# MSPM0G350X register map
Vendor: Texas Instruments; File version: This preliminary header file does not have a version number - build date: 2023-02-21 16:25:48
CPU: CM0 r0p1, little endian, MPU, no FPU, 3 interrupt priority bits
Registers are 32-bit, read-write, reset 0x0 unless marked. A register's access mark holds for its fields unless they carry their own. Offsets are from the block's base; [hi:lo] are bit positions; {n}, {i} and the like mark numbered series.

## SPI1 — PERIPHERALREGION
Base 0x4046A000
Same registers: SPI0 0x40468000
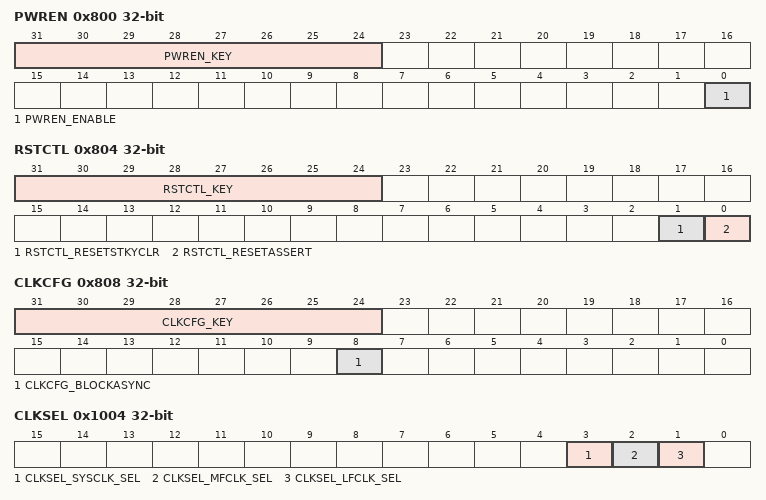
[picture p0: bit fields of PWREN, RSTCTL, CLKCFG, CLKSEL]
0x800 PWREN — Power enable
  [31:24] PWREN_KEY wo — KEY to allow Power State Change
    38=PWREN_KEY_UNLOCK_W (_TO_UNLOCK_W_)
  [0] PWREN_ENABLE — Enable the power
    0=PWREN_ENABLE_DISABLE (DISABLE); 1=PWREN_ENABLE_ENABLE (ENABLE)
0x804 RSTCTL wo — Reset Control
  [31:24] RSTCTL_KEY — Unlock key
    177=RSTCTL_KEY_UNLOCK_W (_TO_UNLOCK_W_)
  [1] RSTCTL_RESETSTKYCLR — Clear the RESETSTKY bit in the STAT register
    0=RSTCTL_RESETSTKYCLR_NOP (NOP); 1=RSTCTL_RESETSTKYCLR_CLR (CLR)
  [0] RSTCTL_RESETASSERT — Assert reset to the peripheral
    0=RSTCTL_RESETASSERT_NOP (NOP); 1=RSTCTL_RESETASSERT_ASSERT (ASSERT)
0x808 CLKCFG — Peripheral Clock Configuration Register
  [31:24] CLKCFG_KEY wo — KEY to Allow State Change -- 0xA9
    169=CLKCFG_KEY_UNLOCK (_UNLOCK_W_)
  [8] CLKCFG_BLOCKASYNC — Async Clock Request is blocked from starting SYSOSC or forcing bus clock to 32MHz
    0=CLKCFG_BLOCKASYNC_DISABLE (DISABLE); 1=CLKCFG_BLOCKASYNC_ENABLE (ENABLE)
0x814 GPRCM_STAT ro — Status Register
  [16] GPRCM_STAT_RESETSTKY — This bit indicates, if the peripheral was reset, since this bit was cleared by RESETSTKYCLR in the RSTCTL register
    0=GPRCM_STAT_RESETSTKY_NORES (NORES); 1=GPRCM_STAT_RESETSTKY_RESET (RESET)
0x1000 CLKDIV — Clock Divider
  [2:0] CLKDIV_RATIO — Selects divide ratio of module clock
    {v}=CLKDIV_RATIO_DIV_BY_{v+1} (DIV_BY_{v+1}) (v=0..7)
0x1004 CLKSEL — Clock Select for Ultra Low Power peripherals
  [3] CLKSEL_SYSCLK_SEL — Selects SYSCLK as clock source if enabled
    0=CLKSEL_SYSCLK_SEL_DISABLE (DISABLE); 1=CLKSEL_SYSCLK_SEL_ENABLE (ENABLE)
  [2] CLKSEL_MFCLK_SEL — Selects MFCLK as clock source if enabled
    0=CLKSEL_MFCLK_SEL_DISABLE (DISABLE); 1=CLKSEL_MFCLK_SEL_ENABLE (ENABLE)
  [1] CLKSEL_LFCLK_SEL — Selects LFCLK as clock source if enabled
    0=CLKSEL_LFCLK_SEL_DISABLE (DISABLE); 1=CLKSEL_LFCLK_SEL_ENABLE (ENABLE)
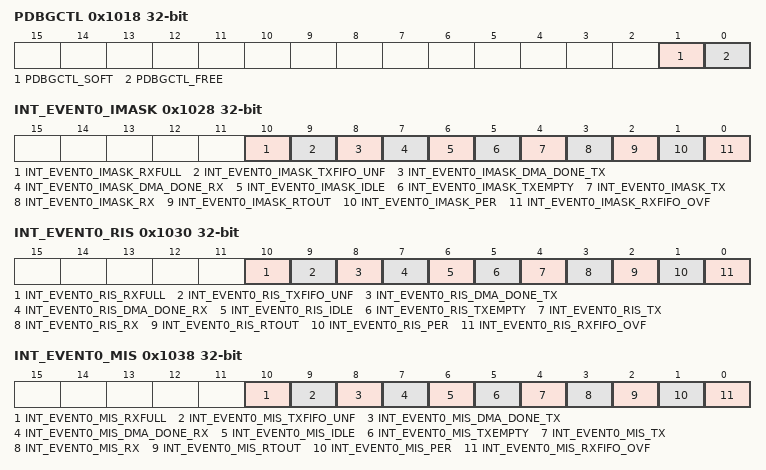
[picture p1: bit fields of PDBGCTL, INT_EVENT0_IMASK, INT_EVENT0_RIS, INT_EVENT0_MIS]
0x1018 PDBGCTL — Peripheral Debug Control
  [1] PDBGCTL_SOFT — Soft halt boundary control. This function is only available, if [FREE] is set to 'STOP'
    0=PDBGCTL_SOFT_IMMEDIATE (IMMEDIATE); 1=PDBGCTL_SOFT_DELAYED (DELAYED)
  [0] PDBGCTL_FREE — Free run control
    0=PDBGCTL_FREE_STOP (STOP); 1=PDBGCTL_FREE_RUN (RUN)
0x1020 INT_EVENT0_IIDX ro — Interrupt Index Register
  [7:0] INT_EVENT0_IIDX_STAT — Interrupt index status
    0=INT_EVENT0_IIDX_STAT_NO_INTR (NO_INTR); 1=INT_EVENT0_IIDX_STAT_RXFIFO_OFV_EVT (RXFIFO_OFV_EVT); 2=INT_EVENT0_IIDX_STAT_PER_EVT (PER_EVT); 3=INT_EVENT0_IIDX_STAT_RTOUT_EVT (RTOUT_EVT); 4=INT_EVENT0_IIDX_STAT_RX_EVT (RX_EVT); 5=INT_EVENT0_IIDX_STAT_TX_EVT (TX_EVT); 6=INT_EVENT0_IIDX_STAT_TX_EMPTY (TX_EMPTY); 7=INT_EVENT0_IIDX_STAT_IDLE_EVT (IDLE_EVT); 8=INT_EVENT0_IIDX_STAT_DMA_DONE_RX_EVT (DMA_DONE_RX_EVT); 9=INT_EVENT0_IIDX_STAT_DMA_DONE_TX_EVT (DMA_DONE_TX_EVT); 10=INT_EVENT0_IIDX_STAT_TXFIFO_UNF_EVT (TXFIFO_UNF_EVT); 11=INT_EVENT0_IIDX_STAT_RXFULL_EVT (RXFULL_EVT)
0x1028 INT_EVENT0_IMASK — Interrupt mask
  [10] INT_EVENT0_IMASK_RXFULL — RX FIFO Full Interrupt Mask
    0=INT_EVENT0_IMASK_RXFULL_CLR (CLR); 1=INT_EVENT0_IMASK_RXFULL_SET (SET)
  [9] INT_EVENT0_IMASK_TXFIFO_UNF — TX FIFO underflow interrupt mask
    0=INT_EVENT0_IMASK_TXFIFO_UNF_CLR (CLR); 1=INT_EVENT0_IMASK_TXFIFO_UNF_SET (SET)
  [8] INT_EVENT0_IMASK_DMA_DONE_TX — DMA Done 1 event for TX event mask.
    0=INT_EVENT0_IMASK_DMA_DONE_TX_CLR (CLR); 1=INT_EVENT0_IMASK_DMA_DONE_TX_SET (SET)
  [7] INT_EVENT0_IMASK_DMA_DONE_RX — DMA Done 1 event for RX event mask.
    0=INT_EVENT0_IMASK_DMA_DONE_RX_CLR (CLR); 1=INT_EVENT0_IMASK_DMA_DONE_RX_SET (SET)
  [6] INT_EVENT0_IMASK_IDLE — SPI Idle event mask.
    0=INT_EVENT0_IMASK_IDLE_CLR (CLR); 1=INT_EVENT0_IMASK_IDLE_SET (SET)
  [5] INT_EVENT0_IMASK_TXEMPTY — Transmit FIFO Empty event mask.
    0=INT_EVENT0_IMASK_TXEMPTY_CLR (CLR); 1=INT_EVENT0_IMASK_TXEMPTY_SET (SET)
  [4] INT_EVENT0_IMASK_TX — Transmit FIFO event mask.
    0=INT_EVENT0_IMASK_TX_CLR (CLR); 1=INT_EVENT0_IMASK_TX_SET (SET)
  [3] INT_EVENT0_IMASK_RX — Receive FIFO event.This interrupt is set if the selected Receive FIFO level has been reached
    0=INT_EVENT0_IMASK_RX_CLR (CLR); 1=INT_EVENT0_IMASK_RX_SET (SET)
  [2] INT_EVENT0_IMASK_RTOUT — Enable SPI Receive Time-Out event mask.
    0=INT_EVENT0_IMASK_RTOUT_CLR (CLR); 1=INT_EVENT0_IMASK_RTOUT_SET (SET)
  [1] INT_EVENT0_IMASK_PER — Parity error event mask.
    0=INT_EVENT0_IMASK_PER_CLR (CLR); 1=INT_EVENT0_IMASK_PER_SET (SET)
  [0] INT_EVENT0_IMASK_RXFIFO_OVF — RXFIFO overflow event mask.
    0=INT_EVENT0_IMASK_RXFIFO_OVF_CLR (CLR); 1=INT_EVENT0_IMASK_RXFIFO_OVF_SET (SET)
0x1030 INT_EVENT0_RIS ro — Raw interrupt status
  [10] INT_EVENT0_RIS_RXFULL — RX FIFO Full Interrupt
    0=INT_EVENT0_RIS_RXFULL_CLR (CLR); 1=INT_EVENT0_RIS_RXFULL_SET (SET)
  [9] INT_EVENT0_RIS_TXFIFO_UNF — TX FIFO Underflow Interrupt
    0=INT_EVENT0_RIS_TXFIFO_UNF_CLR (CLR); 1=INT_EVENT0_RIS_TXFIFO_UNF_SET (SET)
  [8] INT_EVENT0_RIS_DMA_DONE_TX — DMA Done 1 event for TX. This interrupt is set if the TX DMA channel sends the DONE signal. This allows the handling of the DMA event inside the mapped peripheral.
    0=INT_EVENT0_RIS_DMA_DONE_TX_CLR (CLR); 1=INT_EVENT0_RIS_DMA_DONE_TX_SET (SET)
  [7] INT_EVENT0_RIS_DMA_DONE_RX — DMA Done 1 event for RX. This interrupt is set if the RX DMA channel sends the DONE signal. This allows the handling of the DMA event inside the mapped peripheral.
    0=INT_EVENT0_RIS_DMA_DONE_RX_CLR (CLR); 1=INT_EVENT0_RIS_DMA_DONE_RX_SET (SET)
  [6] INT_EVENT0_RIS_IDLE — SPI has done finished transfers and changed into IDLE mode. This bit is set when BUSY goes low.
    0=INT_EVENT0_RIS_IDLE_CLR (CLR); 1=INT_EVENT0_RIS_IDLE_SET (SET)
  [5] INT_EVENT0_RIS_TXEMPTY — Transmit FIFO Empty interrupt mask. This interrupt is set if all data in the Transmit FIFO have been move to the shift register.
    0=INT_EVENT0_RIS_TXEMPTY_CLR (CLR); 1=INT_EVENT0_RIS_TXEMPTY_SET (SET)
  [4] INT_EVENT0_RIS_TX — Transmit FIFO event..This interrupt is set if the selected Transmit FIFO level has been reached.
    0=INT_EVENT0_RIS_TX_CLR (CLR); 1=INT_EVENT0_RIS_TX_SET (SET)
  [3] INT_EVENT0_RIS_RX — Receive FIFO event.This interrupt is set if the selected Receive FIFO level has been reached
    0=INT_EVENT0_RIS_RX_CLR (CLR); 1=INT_EVENT0_RIS_RX_SET (SET)
  [2] INT_EVENT0_RIS_RTOUT — SPI Receive Time-Out event.
    0=INT_EVENT0_RIS_RTOUT_CLR (CLR); 1=INT_EVENT0_RIS_RTOUT_SET (SET)
  [1] INT_EVENT0_RIS_PER — Parity error event: this bit is set if a Parity error has been detected
    0=INT_EVENT0_RIS_PER_CLR (CLR); 1=INT_EVENT0_RIS_PER_SET (SET)
  [0] INT_EVENT0_RIS_RXFIFO_OVF — RXFIFO overflow event. This interrupt is set if an RX FIFO overflow has been detected.
    0=INT_EVENT0_RIS_RXFIFO_OVF_CLR (CLR); 1=INT_EVENT0_RIS_RXFIFO_OVF_SET (SET)
0x1038 INT_EVENT0_MIS ro — Masked interrupt status
  [10] INT_EVENT0_MIS_RXFULL — RX FIFO Full Interrupt
    0=INT_EVENT0_MIS_RXFULL_CLR (CLR); 1=INT_EVENT0_MIS_RXFULL_SET (SET)
  [9] INT_EVENT0_MIS_TXFIFO_UNF — TX FIFO underflow interrupt
    0=INT_EVENT0_MIS_TXFIFO_UNF_CLR (CLR); 1=INT_EVENT0_MIS_TXFIFO_UNF_SET (SET)
  [8] INT_EVENT0_MIS_DMA_DONE_TX — Masked DMA Done 1 event for TX.
    0=INT_EVENT0_MIS_DMA_DONE_TX_CLR (CLR); 1=INT_EVENT0_MIS_DMA_DONE_TX_SET (SET)
  [7] INT_EVENT0_MIS_DMA_DONE_RX — Masked DMA Done 1 event for RX.
    0=INT_EVENT0_MIS_DMA_DONE_RX_CLR (CLR); 1=INT_EVENT0_MIS_DMA_DONE_RX_SET (SET)
  [6] INT_EVENT0_MIS_IDLE — Masked SPI IDLE mode event.
    0=INT_EVENT0_MIS_IDLE_CLR (CLR); 1=INT_EVENT0_MIS_IDLE_SET (SET)
  [5] INT_EVENT0_MIS_TXEMPTY — Masked Transmit FIFO Empty event.
    0=INT_EVENT0_MIS_TXEMPTY_CLR (CLR); 1=INT_EVENT0_MIS_TXEMPTY_SET (SET)
  [4] INT_EVENT0_MIS_TX — Masked Transmit FIFO event. This interrupt is set if the selected Transmit FIFO level has been reached.
    0=INT_EVENT0_MIS_TX_CLR (CLR); 1=INT_EVENT0_MIS_TX_SET (SET)
  [3] INT_EVENT0_MIS_RX — Masked receive FIFO event.This interrupt is set if the selected Receive FIFO level has been reached
    0=INT_EVENT0_MIS_RX_CLR (CLR); 1=INT_EVENT0_MIS_RX_SET (SET)
  [2] INT_EVENT0_MIS_RTOUT — Masked SPI Receive Time-Out Interrupt.
    0=INT_EVENT0_MIS_RTOUT_CLR (CLR); 1=INT_EVENT0_MIS_RTOUT_SET (SET)
  [1] INT_EVENT0_MIS_PER — Masked Parity error event: this bit if a Parity error has been detected
    0=INT_EVENT0_MIS_PER_CLR (CLR); 1=INT_EVENT0_MIS_PER_SET (SET)
  [0] INT_EVENT0_MIS_RXFIFO_OVF — Masked RXFIFO overflow event. This interrupt is set if an RX FIFO overflow has been detected.
    0=INT_EVENT0_MIS_RXFIFO_OVF_CLR (CLR); 1=INT_EVENT0_MIS_RXFIFO_OVF_SET (SET)
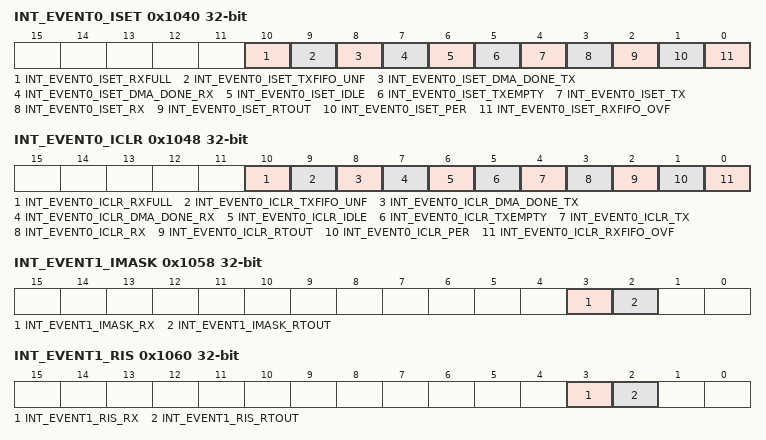
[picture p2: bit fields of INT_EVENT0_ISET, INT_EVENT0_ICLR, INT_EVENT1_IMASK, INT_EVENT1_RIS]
0x1040 INT_EVENT0_ISET wo — Interrupt set
  [10] INT_EVENT0_ISET_RXFULL — Set RX FIFO Full Event
    0=INT_EVENT0_ISET_RXFULL_NO_EFFECT (NO_EFFECT); 1=INT_EVENT0_ISET_RXFULL_SET (SET)
  [9] INT_EVENT0_ISET_TXFIFO_UNF — Set TX FIFO Underflow Event
    0=INT_EVENT0_ISET_TXFIFO_UNF_NO_EFFECT (NO_EFFECT); 1=INT_EVENT0_ISET_TXFIFO_UNF_SET (SET)
  [8] INT_EVENT0_ISET_DMA_DONE_TX — Set DMA Done 1 event for TX.
    0=INT_EVENT0_ISET_DMA_DONE_TX_NO_EFFECT (NO_EFFECT); 1=INT_EVENT0_ISET_DMA_DONE_TX_SET (SET)
  [7] INT_EVENT0_ISET_DMA_DONE_RX — Set DMA Done 1 event for RX.
    0=INT_EVENT0_ISET_DMA_DONE_RX_NO_EFFECT (NO_EFFECT); 1=INT_EVENT0_ISET_DMA_DONE_RX_SET (SET)
  [6] INT_EVENT0_ISET_IDLE — Set SPI IDLE mode event.
    0=INT_EVENT0_ISET_IDLE_NO_EFFECT (NO_EFFECT); 1=INT_EVENT0_ISET_IDLE_SET (SET)
  [5] INT_EVENT0_ISET_TXEMPTY — Set Transmit FIFO Empty event.
    0=INT_EVENT0_ISET_TXEMPTY_NO_EFFECT (NO_EFFECT); 1=INT_EVENT0_ISET_TXEMPTY_SET (SET)
  [4] INT_EVENT0_ISET_TX — Set Transmit FIFO event.
    0=INT_EVENT0_ISET_TX_NO_EFFECT (NO_EFFECT); 1=INT_EVENT0_ISET_TX_SET (SET)
  [3] INT_EVENT0_ISET_RX — Set Receive FIFO event.
    0=INT_EVENT0_ISET_RX_NO_EFFECT (NO_EFFECT); 1=INT_EVENT0_ISET_RX_SET (SET)
  [2] INT_EVENT0_ISET_RTOUT — Set SPI Receive Time-Out Event.
    0=INT_EVENT0_ISET_RTOUT_NO_EFFECT (NO_EFFECT); 1=INT_EVENT0_ISET_RTOUT_SET (SET)
  [1] INT_EVENT0_ISET_PER — Set Parity error event.
    0=INT_EVENT0_ISET_PER_NO_EFFECT (NO_EFFECT); 1=INT_EVENT0_ISET_PER_SET (SET)
  [0] INT_EVENT0_ISET_RXFIFO_OVF — Set RXFIFO overflow event.
    0=INT_EVENT0_ISET_RXFIFO_OVF_NO_EFFECT (NO_EFFECT); 1=INT_EVENT0_ISET_RXFIFO_OVF_SET (SET)
0x1048 INT_EVENT0_ICLR wo — Interrupt clear
  [10] INT_EVENT0_ICLR_RXFULL — Clear RX FIFO underflow event
    0=INT_EVENT0_ICLR_RXFULL_NO_EFFECT (NO_EFFECT); 1=INT_EVENT0_ICLR_RXFULL_CLR (CLR)
  [9] INT_EVENT0_ICLR_TXFIFO_UNF — Clear TXFIFO underflow event
    0=INT_EVENT0_ICLR_TXFIFO_UNF_NO_EFFECT (NO_EFFECT); 1=INT_EVENT0_ICLR_TXFIFO_UNF_CLR (CLR)
  [8] INT_EVENT0_ICLR_DMA_DONE_TX — Clear DMA Done 1 event for TX.
    0=INT_EVENT0_ICLR_DMA_DONE_TX_NO_EFFECT (NO_EFFECT); 1=INT_EVENT0_ICLR_DMA_DONE_TX_CLR (CLR)
  [7] INT_EVENT0_ICLR_DMA_DONE_RX — Clear DMA Done 1 event for RX.
    0=INT_EVENT0_ICLR_DMA_DONE_RX_NO_EFFECT (NO_EFFECT); 1=INT_EVENT0_ICLR_DMA_DONE_RX_CLR (CLR)
  [6] INT_EVENT0_ICLR_IDLE — Clear SPI IDLE mode event.
    0=INT_EVENT0_ICLR_IDLE_NO_EFFECT (NO_EFFECT); 1=INT_EVENT0_ICLR_IDLE_CLR (CLR)
  [5] INT_EVENT0_ICLR_TXEMPTY — Clear Transmit FIFO Empty event.
    0=INT_EVENT0_ICLR_TXEMPTY_NO_EFFECT (NO_EFFECT); 1=INT_EVENT0_ICLR_TXEMPTY_CLR (CLR)
  [4] INT_EVENT0_ICLR_TX — Clear Transmit FIFO event.
    0=INT_EVENT0_ICLR_TX_NO_EFFECT (NO_EFFECT); 1=INT_EVENT0_ICLR_TX_CLR (CLR)
  [3] INT_EVENT0_ICLR_RX — Clear Receive FIFO event.
    0=INT_EVENT0_ICLR_RX_NO_EFFECT (NO_EFFECT); 1=INT_EVENT0_ICLR_RX_CLR (CLR)
  [2] INT_EVENT0_ICLR_RTOUT — Clear SPI Receive Time-Out Event.
    0=INT_EVENT0_ICLR_RTOUT_NO_EFFECT (NO_EFFECT); 1=INT_EVENT0_ICLR_RTOUT_CLR (CLR)
  [1] INT_EVENT0_ICLR_PER — Clear Parity error event.
    0=INT_EVENT0_ICLR_PER_NO_EFFECT (NO_EFFECT); 1=INT_EVENT0_ICLR_PER_CLR (CLR)
  [0] INT_EVENT0_ICLR_RXFIFO_OVF — Clear RXFIFO overflow event.
    0=INT_EVENT0_ICLR_RXFIFO_OVF_NO_EFFECT (NO_EFFECT); 1=INT_EVENT0_ICLR_RXFIFO_OVF_CLR (CLR)
0x1050 INT_EVENT1_IIDX ro — Interrupt Index Register
  [7:0] INT_EVENT1_IIDX_STAT — Interrupt index status
    0=INT_EVENT1_IIDX_STAT_NO_INTR (NO_INTR); 3=INT_EVENT1_IIDX_STAT_RTOUT_EVT (RTOUT_EVT); 4=INT_EVENT1_IIDX_STAT_RX_EVT (RX_EVT)
0x1058 INT_EVENT1_IMASK — Interrupt mask
  [3] INT_EVENT1_IMASK_RX — Receive FIFO event mask.
    0=INT_EVENT1_IMASK_RX_CLR (CLR); 1=INT_EVENT1_IMASK_RX_SET (SET)
  [2] INT_EVENT1_IMASK_RTOUT — SPI Receive Time-Out event mask.
    0=INT_EVENT1_IMASK_RTOUT_CLR (CLR); 1=INT_EVENT1_IMASK_RTOUT_SET (SET)
0x1060 INT_EVENT1_RIS ro — Raw interrupt status
  [3] INT_EVENT1_RIS_RX — Receive FIFO event.This interrupt is set if the selected Receive FIFO level has been reached
    0=INT_EVENT1_RIS_RX_CLR (CLR); 1=INT_EVENT1_RIS_RX_SET (SET)
  [2] INT_EVENT1_RIS_RTOUT — SPI Receive Time-Out Event.
    0=INT_EVENT1_RIS_RTOUT_CLR (CLR); 1=INT_EVENT1_RIS_RTOUT_SET (SET)
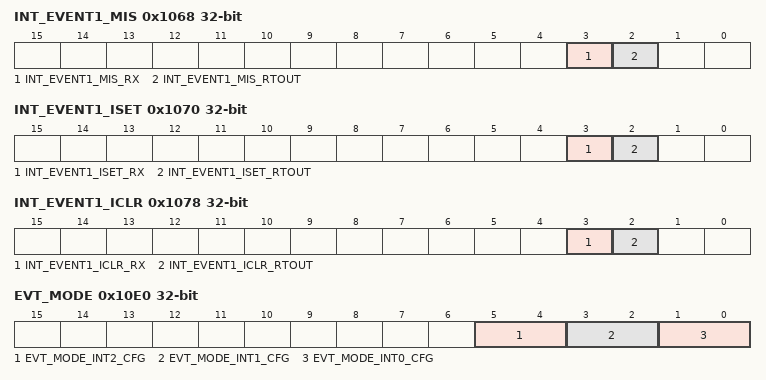
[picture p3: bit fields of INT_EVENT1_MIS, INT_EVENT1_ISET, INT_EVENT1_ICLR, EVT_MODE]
0x1068 INT_EVENT1_MIS ro — Masked interrupt status
  [3] INT_EVENT1_MIS_RX — Receive FIFO event mask.
    0=INT_EVENT1_MIS_RX_CLR (CLR); 1=INT_EVENT1_MIS_RX_SET (SET)
  [2] INT_EVENT1_MIS_RTOUT — SPI Receive Time-Out event mask.
    0=INT_EVENT1_MIS_RTOUT_CLR (CLR); 1=INT_EVENT1_MIS_RTOUT_SET (SET)
0x1070 INT_EVENT1_ISET wo — Interrupt set
  [3] INT_EVENT1_ISET_RX — Set Receive FIFO event.
    0=INT_EVENT1_ISET_RX_NO_EFFECT (NO_EFFECT); 1=INT_EVENT1_ISET_RX_SET (SET)
  [2] INT_EVENT1_ISET_RTOUT — Set SPI Receive Time-Out event.
    0=INT_EVENT1_ISET_RTOUT_NO_EFFECT (NO_EFFECT); 1=INT_EVENT1_ISET_RTOUT_SET (SET)
0x1078 INT_EVENT1_ICLR wo — Interrupt clear
  [3] INT_EVENT1_ICLR_RX — Clear Receive FIFO event.
    0=INT_EVENT1_ICLR_RX_NO_EFFECT (NO_EFFECT); 1=INT_EVENT1_ICLR_RX_CLR (CLR)
  [2] INT_EVENT1_ICLR_RTOUT — Clear SPI Receive Time-Out event.
    0=INT_EVENT1_ICLR_RTOUT_NO_EFFECT (NO_EFFECT); 1=INT_EVENT1_ICLR_RTOUT_CLR (CLR)
0x1080 INT_EVENT2_IIDX ro — Interrupt Index Register
  [7:0] INT_EVENT2_IIDX_STAT — Interrupt index status
    0=INT_EVENT2_IIDX_STAT_NO_INTR (NO_INTR); 5=INT_EVENT2_IIDX_STAT_TX_EVT (TX_EVT)
0x1088 INT_EVENT2_IMASK — Interrupt mask
  [4] INT_EVENT2_IMASK_TX — Transmit FIFO event mask.
    0=INT_EVENT2_IMASK_TX_CLR (CLR); 1=INT_EVENT2_IMASK_TX_SET (SET)
0x1090 INT_EVENT2_RIS ro — Raw interrupt status
  [4] INT_EVENT2_RIS_TX — Transmit FIFO event: A read returns the current mask for transmit FIFO interrupt. On a write of 1, the mask for transmit FIFO interrupt is set which means the interrupt state will be reflected in MIS.TXMIS. A write of 0 clears the mask which means MIS.TXMIS will not reflect the interrupt.
    0=INT_EVENT2_RIS_TX_CLR (CLR); 1=INT_EVENT2_RIS_TX_SET (SET)
0x1098 INT_EVENT2_MIS ro — Masked interrupt status
  [4] INT_EVENT2_MIS_TX — Masked Transmit FIFO event
    0=INT_EVENT2_MIS_TX_CLR (CLR); 1=INT_EVENT2_MIS_TX_SET (SET)
0x10A0 INT_EVENT2_ISET wo — Interrupt set
  [4] INT_EVENT2_ISET_TX — Set Transmit FIFO event.
    0=INT_EVENT2_ISET_TX_NO_EFFECT (NO_EFFECT); 1=INT_EVENT2_ISET_TX_SET (SET)
0x10A8 INT_EVENT2_ICLR wo — Interrupt clear
  [4] INT_EVENT2_ICLR_TX — Clear Transmit FIFO event.
    0=INT_EVENT2_ICLR_TX_NO_EFFECT (NO_EFFECT); 1=INT_EVENT2_ICLR_TX_CLR (CLR)
0x10E0 EVT_MODE — Event Mode
  [5:4] EVT_MODE_INT2_CFG ro — Event line mode select for event corresponding to [IPSTANDARD.INT_EVENT2]
    0=EVT_MODE_INT2_CFG_DISABLE (DISABLE); 1=EVT_MODE_INT2_CFG_SOFTWARE (SOFTWARE); 2=EVT_MODE_INT2_CFG_HARDWARE (HARDWARE)
  [3:2] EVT_MODE_INT1_CFG ro — Event line mode select for event corresponding to [IPSTANDARD.INT_EVENT1]
    0=EVT_MODE_INT1_CFG_DISABLE (DISABLE); 1=EVT_MODE_INT1_CFG_SOFTWARE (SOFTWARE); 2=EVT_MODE_INT1_CFG_HARDWARE (HARDWARE)
  [1:0] EVT_MODE_INT0_CFG ro — Event line mode select for event corresponding to [IPSTANDARD.INT_EVENT0]
    0=EVT_MODE_INT0_CFG_DISABLE (DISABLE); 1=EVT_MODE_INT0_CFG_SOFTWARE (SOFTWARE); 2=EVT_MODE_INT0_CFG_HARDWARE (HARDWARE)
0x10E4 INTCTL — Interrupt control register
  [0] INTCTL_INTEVAL wo — Writing a 1 to this field re-evaluates the interrupt sources.
    0=INTCTL_INTEVAL_DISABLE (DISABLE); 1=INTCTL_INTEVAL_EVAL (EVAL)
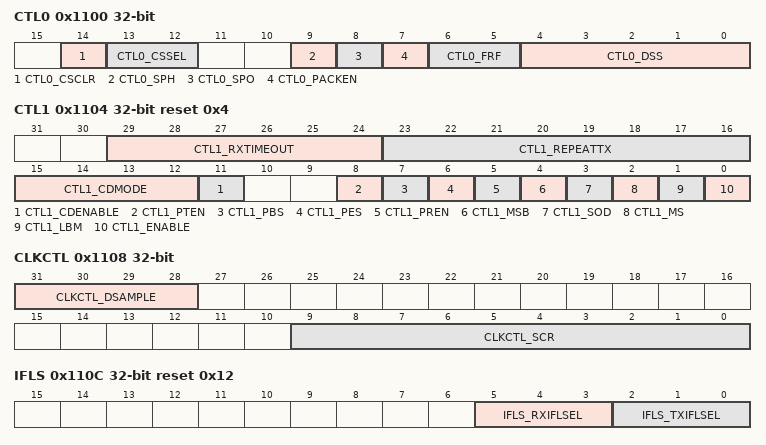
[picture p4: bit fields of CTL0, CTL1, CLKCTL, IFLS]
0x1100 CTL0 — SPI control register 0
  [14] CTL0_CSCLR — Clear shift register counter on CS inactive This bit is relevant only in the peripheral, CTL1.MS=0.
    0=CTL0_CSCLR_DISABLE (DISABLE); 1=CTL0_CSCLR_ENABLE (ENABLE)
  [13:12] CTL0_CSSEL — Select the CS line to control on data transfer This bit is for controller mode only.
    {v}=CTL0_CSSEL_CSSEL_{v} (CSSEL_{v}) (v=0..3)
  [9] CTL0_SPH — CLKOUT phase (Motorola SPI frame format only) This bit selects the clock edge that captures data and enables it to change state. It has the most impact on the first bit transmitted by either permitting or not permitting a clock transition before the first data capture edge.
    0=CTL0_SPH_FIRST (FIRST); 1=CTL0_SPH_SECOND (SECOND)
  [8] CTL0_SPO — CLKOUT polarity (Motorola SPI frame format only)
    0=CTL0_SPO_LOW (LOW); 1=CTL0_SPO_HIGH (HIGH)
  [7] CTL0_PACKEN — Packing Enable. When 1, packing feature is enabled inside the IP When 0, packing feature is disabled inside the IP
    0=CTL0_PACKEN_DISABLED (DISABLED); 1=CTL0_PACKEN_ENABLED (ENABLED)
  [6:5] CTL0_FRF — Frame format Select
    0=CTL0_FRF_MOTOROLA_3WIRE (MOTOROLA_3WIRE); 1=CTL0_FRF_MOTOROLA_4WIRE (MOTOROLA_4WIRE); 2=CTL0_FRF_TI_SYNC (TI_SYNC); 3=CTL0_FRF_MIRCOWIRE (MIRCOWIRE)
  [4:0] CTL0_DSS — Data Size Select. Values 0 - 2 are reserved and shall not be used. 3h = 4_BIT : 4-bit data SPI allows only values up to 16 Bit
    {v}=CTL0_DSS_DSS_{v+1} (DSS_{v+1}) (v=3..15); 31=CTL0_DSS_DSS_32 (DSS_32)
0x1104 CTL1 reset 0x4 — SPI control register 1
  [29:24] CTL1_RXTIMEOUT — Receive Timeout (only for Peripheral mode) Defines the number of Clock Cycles before after which the Receive Timeout flag RTOUT is set. The time is calculated using the control register for the clock selection and divider in the Controller mode configuration. A value of 0 disables this function.
  [23:16] CTL1_REPEATTX — Counter to repeat last transfer 0: repeat last transfer is disabled. x: repeat the last transfer with the given number. The transfer will be started with writing a data into the TX Buffer. Sending the data will be repeated with the given value, so the data will be transferred X+1 times in total. The behavior is identical as if the data would be written into the TX Buffer that many times as defined by the value here. It can be used to clean a transfer or to pull a certain amount of data by a peripheral.
    0=CTL1_REPEATTX_DISABLE (DISABLE)
  [15:12] CTL1_CDMODE — Command/Data Mode Value When CTL1.CDENABLE is 1, CS3 line is used as C/D signal to distinguish between Command (C/D low) and Data (C/D high) information. When a value is written into the CTL1.CDMODE bits, the C/D (CS3) line will go low for the given numbers of byte which are sent by the SPI, starting with the next value to be transmitted after which, C/D line will go high automatically 0: Manual mode with C/D signal as High 1-14: C/D is low while this number of bytes are being sent after which, this field sets to 0 and C/D goes high. Reading this field at any time returns the remaining number of command bytes. 15: Manual mode with C/D signal as Low.
    0=CTL1_CDMODE_DATA (DATA); 15=CTL1_CDMODE_COMMAND (COMMAND)
  [11] CTL1_CDENABLE — Command/Data Mode enable
    0=CTL1_CDENABLE_DISABLE (DISABLE); 1=CTL1_CDENABLE_ENABLE (ENABLE)
  [8] CTL1_PTEN — Parity transmit enable If enabled, parity transmission will be done for both controller and peripheral modes.
    0=CTL1_PTEN_DISABLE (DISABLE); 1=CTL1_PTEN_ENABLE (ENABLE)
  [7] CTL1_PBS — Parity Bit Select
    0=CTL1_PBS_DISABLE (DISABLE); 1=CTL1_PBS_ENABLE (ENABLE)
  [6] CTL1_PES — Even Parity Select
    0=CTL1_PES_DISABLE (DISABLE); 1=CTL1_PES_ENABLE (ENABLE)
  [5] CTL1_PREN — Parity receive enable If enabled, parity reception check will be done for both controller and peripheral modes In case of a parity miss-match the parity error flag RIS.PER will be set.
    0=CTL1_PREN_DISABLE (DISABLE); 1=CTL1_PREN_ENABLE (ENABLE)
  [4] CTL1_MSB — MSB first select. Controls the direction of the receive and transmit shift register.
    0=CTL1_MSB_DISABLE (DISABLE); 1=CTL1_MSB_ENABLE (ENABLE)
  [3] CTL1_SOD — Peripheral-mode: Data output disabled This bit is relevant only in the peripheral mode, CTL1.MS=1. In multiple-peripheral systems, it is possible for an SPI controller to broadcast a message to all peripherals in the system while ensuring that only one peripheral drives data onto its serial output line. In such systems the MISO lines from multiple peripherals could be tied together. To operate in such systems, this bitfield can be set if the SPI peripheral is not supposed to drive the MISO line:
    0=CTL1_SOD_DISABLE (DISABLE); 1=CTL1_SOD_ENABLE (ENABLE)
  [2] CTL1_MS — Controller or peripheral mode select. This bit can be modified only when SPI is disabled, CTL1.ENABLE=0.
    0=CTL1_MS_DISABLE (DISABLE); 1=CTL1_MS_ENABLE (ENABLE)
  [1] CTL1_LBM — Loop back mode
    0=CTL1_LBM_DISABLE (DISABLE); 1=CTL1_LBM_ENABLE (ENABLE)
  [0] CTL1_ENABLE — SPI enable
    0=CTL1_ENABLE_DISABLE (DISABLE); 1=CTL1_ENABLE_ENABLE (ENABLE)
0x1108 CLKCTL — Clock prescaler and divider register.
  [31:28] CLKCTL_DSAMPLE — Delayed sampling value. In controller mode the data on the input pin will be delayed sampled by the defined clock cycles of internal functional clock hence relaxing the setup time of input data. This setting is useful in systems where the board delays and external peripheral delays are more than the input setup time of the controller. Please refer to the datasheet for values of controller input setup time and assess what DSAMPLE value meets the requirement of the system. Note: High values of DSAMPLE can cause HOLD time violations and must be factored in the calculations.
  [9:0] CLKCTL_SCR — Serial clock divider: This is used to generate the transmit and receive bit rate of the SPI. The SPI bit rate is (SPI's functional clock frequency)/((SCR+1)*2). SCR is a value from 0-1023.
0x110C IFLS reset 0x12 — UART Interrupt FIFO Level Select Register
  [5:3] IFLS_RXIFLSEL — SPI Receive Interrupt FIFO Level Select The trigger points for the receive interrupt are as follows:
    0=IFLS_RXIFLSEL_LVL_OFF (LVL_OFF); 1=IFLS_RXIFLSEL_LVL_1_4 (LVL_1_4); 2=IFLS_RXIFLSEL_LVL_1_2 (LVL_1_2); 3=IFLS_RXIFLSEL_LVL_3_4 (LVL_3_4); 4=IFLS_RXIFLSEL_LVL_RES4 (LVL_RES4); 5=IFLS_RXIFLSEL_LVL_FULL (LVL_FULL); 6=IFLS_RXIFLSEL_LVL_RES6 (LVL_RES6); 7=IFLS_RXIFLSEL_LEVEL_1 (LEVEL_1)
  [2:0] IFLS_TXIFLSEL — SPI Transmit Interrupt FIFO Level Select The trigger points for the transmit interrupt are as follows:
    0=IFLS_TXIFLSEL_LVL_OFF (LVL_OFF); 1=IFLS_TXIFLSEL_LVL_3_4 (LVL_3_4); 2=IFLS_TXIFLSEL_LVL_1_2 (LVL_1_2); 3=IFLS_TXIFLSEL_LVL_1_4 (LVL_1_4); 4=IFLS_TXIFLSEL_LVL_RES4 (LVL_RES4); 5=IFLS_TXIFLSEL_LVL_EMPTY (LVL_EMPTY); 6=IFLS_TXIFLSEL_LVL_RES6 (LVL_RES6); 7=IFLS_TXIFLSEL_LEVEL_1 (LEVEL_1)
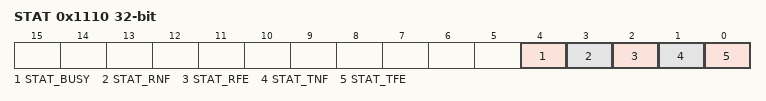
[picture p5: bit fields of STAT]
0x1110 STAT ro — Status Register
  [4] STAT_BUSY — Busy
    0=STAT_BUSY_IDLE (IDLE); 1=STAT_BUSY_ACTIVE (ACTIVE)
  [3] STAT_RNF — Receive FIFO not full
    0=STAT_RNF_FULL (FULL); 1=STAT_RNF_NOT_FULL (NOT_FULL)
  [2] STAT_RFE — Receive FIFO empty.
    0=STAT_RFE_NOT_EMPTY (NOT_EMPTY); 1=STAT_RFE_EMPTY (EMPTY)
  [1] STAT_TNF — Transmit FIFO not full
    0=STAT_TNF_FULL (FULL); 1=STAT_TNF_NOT_FULL (NOT_FULL)
  [0] STAT_TFE — Transmit FIFO empty.
    0=STAT_TFE_NOT_EMPTY (NOT_EMPTY); 1=STAT_TFE_EMPTY (EMPTY)
0x1130 RXDATA ro
  [15:0] RXDATA_DATA — Received Data When PACKEN=1,two entries of the FIFO are returned as a 32-bit value. When PACKEN=0, 1 entry of FIFO is returned as 16-bit value. As data values are removed by the receive logic from the incoming data frame, they are placed into the entry in the receive FIFO, pointed to by the current FIFO write pointer. Received data less than 16 bits is automatically right justified in the receive buffer.
0x1140 TXDATA
  [15:0] TXDATA_DATA — Transmit Data WWhen read, last written value will be returned. If the last write to this field was a 32-bit write (with PACKEN=1), 32-bits will be returned and if the last write was a 16-bit write (PACKEN=0), those 16-bits will be returned. When written, one or two FIFO entries will be written depending on PACKEN value. Data values are removed from the transmit FIFO one value at a time by the transmit logic. It is loaded into the transmit serial shifter, then serially shifted out onto the TXD output pin at the programmed bit rate. When a data size of less than 16 bits is selected, the user must right-justify data written to the transmit FIFO. The transmit logic ignores the unused bits.
